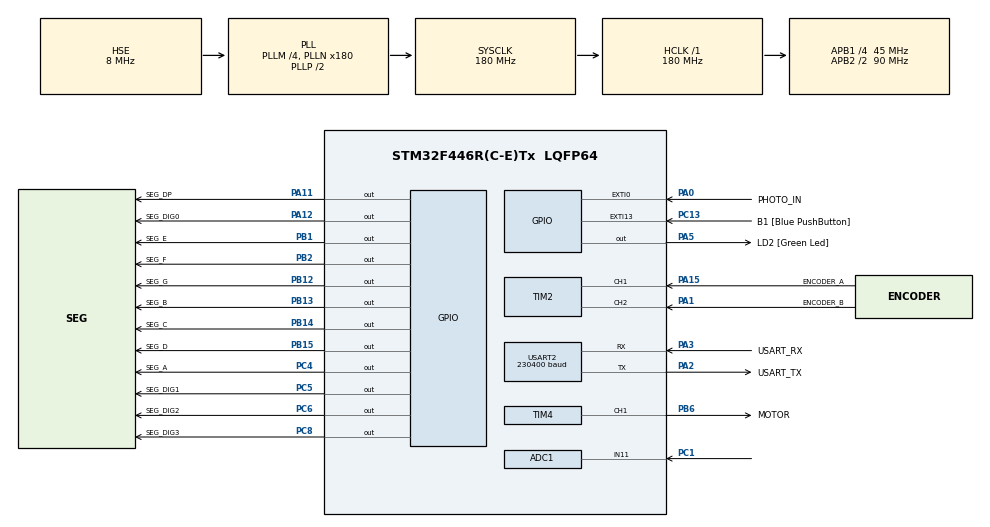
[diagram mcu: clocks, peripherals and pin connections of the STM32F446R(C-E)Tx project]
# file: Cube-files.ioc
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ADC1.Channel-1\#ChannelRegularConversion=ADC_CHANNEL_11
ADC1.ContinuousConvMode=ENABLE
ADC1.DMAContinuousRequests=ENABLE
ADC1.NbrOfConversion=1
ADC1.NbrOfConversionFlag=1
ADC1.Rank-1\#ChannelRegularConversion=1
ADC1.SamplingTime-1\#ChannelRegularConversion=ADC_SAMPLETIME_480CYCLES
ADC1.ScanConvMode=ENABLE
ADC1.master=1
Dma.ADC1.1.Direction=DMA_PERIPH_TO_MEMORY
Dma.ADC1.1.FIFOMode=DMA_FIFOMODE_DISABLE
Dma.ADC1.1.Instance=DMA2_Stream0
Dma.ADC1.1.MemDataAlignment=DMA_MDATAALIGN_WORD
Dma.ADC1.1.MemInc=DMA_MINC_ENABLE
Dma.ADC1.1.Mode=DMA_CIRCULAR
Dma.ADC1.1.PeriphDataAlignment=DMA_PDATAALIGN_WORD
Dma.ADC1.1.PeriphInc=DMA_PINC_DISABLE
Dma.ADC1.1.Priority=DMA_PRIORITY_LOW
Dma.Request0=USART2_TX
Dma.Request1=ADC1
Dma.USART2_TX.0.Direction=DMA_MEMORY_TO_PERIPH
Dma.USART2_TX.0.FIFOMode=DMA_FIFOMODE_DISABLE
Dma.USART2_TX.0.Instance=DMA1_Stream6
Dma.USART2_TX.0.MemDataAlignment=DMA_MDATAALIGN_BYTE
Dma.USART2_TX.0.MemInc=DMA_MINC_ENABLE
Dma.USART2_TX.0.Mode=DMA_NORMAL
Dma.USART2_TX.0.PeriphDataAlignment=DMA_PDATAALIGN_BYTE
Dma.USART2_TX.0.PeriphInc=DMA_PINC_DISABLE
Dma.USART2_TX.0.Priority=DMA_PRIORITY_LOW
FREERTOS.INCLUDE_vTaskDelayUntil=1
FREERTOS.Tasks01=mainTaskName,0,128,mainTask,As weak,NULL,Dynamic,NULL,NULL;printTaskName,-2,128,printTask,As external,NULL,Dynamic,NULL,NULL;motorTaskName,0,512,motorTask,As external,NULL,Dynamic,NULL,NULL;rpmDispTaskNam,-3,256,rpmDisplayTask,As external,NULL,Dynamic,NULL,NULL
FREERTOS.configENABLE_FPU=1
FREERTOS.configUSE_POSIX_ERRNO=0
Mcu.Family=STM32F4
Mcu.Name=STM32F446R(C-E)Tx
Mcu.Package=LQFP64
NVIC.ADC_IRQn=true\:5\:0\:false\:false\:true\:true\:true\:true\:true
NVIC.DMA1_Stream6_IRQn=true\:5\:0\:false\:false\:true\:true\:false\:true\:true
NVIC.DMA2_Stream0_IRQn=true\:5\:0\:false\:false\:true\:true\:false\:true\:true
NVIC.EXTI0_IRQn=true\:5\:0\:false\:false\:true\:true\:true\:true\:true
NVIC.PriorityGroup=NVIC_PRIORITYGROUP_4
NVIC.TIM8_TRG_COM_TIM14_IRQn=true\:15\:0\:false\:false\:true\:false\:false\:true\:true
NVIC.TimeBase=TIM8_TRG_COM_TIM14_IRQn
NVIC.TimeBaseIP=TIM14
NVIC.USART2_IRQn=true\:5\:0\:false\:false\:true\:true\:true\:true\:true
PA0-WKUP.GPIO_Label=PHOTO_IN
PA0-WKUP.GPIO_ModeDefaultEXTI=GPIO_MODE_IT_RISING
PA0-WKUP.GPIO_PuPd=GPIO_PULLDOWN
PA0-WKUP.Signal=GPXTI0
PA1.GPIO_Label=ENCODER_B
PA1.Signal=S_TIM2_CH2
PA11.GPIO_Label=SEG_DP
PA11.GPIO_PuPd=GPIO_PULLDOWN
PA11.Signal=GPIO_Output
PA12.GPIO_Label=SEG_DIG0
PA12.GPIO_PuPd=GPIO_NOPULL
PA12.Signal=GPIO_Output
PA13.GPIO_Label=TMS
PA13.Mode=Serial_Wire
PA13.Signal=SYS_JTMS-SWDIO
PA14.GPIO_Label=TCK
PA14.Mode=Serial_Wire
PA14.Signal=SYS_JTCK-SWCLK
PA15.GPIO_Label=ENCODER_A
PA15.Signal=S_TIM2_CH1_ETR
PA2.GPIO_Label=USART_TX
PA2.Mode=Asynchronous
PA2.Signal=USART2_TX
PA3.GPIO_Label=USART_RX
PA3.Mode=Asynchronous
PA3.Signal=USART2_RX
PA5.GPIO_Label=LD2 [Green Led]
PA5.Signal=GPIO_Output
PB1.GPIO_Label=SEG_E
PB1.GPIO_PuPd=GPIO_NOPULL
PB1.Signal=GPIO_Output
PB12.GPIO_Label=SEG_G
PB12.GPIO_PuPd=GPIO_NOPULL
PB12.Signal=GPIO_Output
PB13.GPIO_Label=SEG_B
PB13.GPIO_PuPd=GPIO_NOPULL
PB13.Signal=GPIO_Output
PB14.GPIO_Label=SEG_C
PB14.GPIO_PuPd=GPIO_NOPULL
PB14.Signal=GPIO_Output
PB15.GPIO_Label=SEG_D
PB15.GPIO_PuPd=GPIO_NOPULL
PB15.Signal=GPIO_Output
PB2.GPIO_Label=SEG_F
PB2.GPIO_PuPd=GPIO_NOPULL
PB2.Signal=GPIO_Output
PB3.GPIO_Label=SWO
PB3.Signal=SYS_JTDO-SWO
PB6.GPIO_Label=MOTOR
PB6.Signal=S_TIM4_CH1
PC1.Signal=ADCx_IN11
PC13.GPIO_Label=B1 [Blue PushButton]
PC13.GPIO_ModeDefaultEXTI=GPIO_MODE_IT_FALLING
PC13.Signal=GPXTI13
PC14-OSC32_IN.Mode=LSE-External-Oscillator
PC14-OSC32_IN.Signal=RCC_OSC32_IN
PC15-OSC32_OUT.Mode=LSE-External-Oscillator
PC15-OSC32_OUT.Signal=RCC_OSC32_OUT
PC4.GPIO_Label=SEG_A
PC4.GPIO_PuPd=GPIO_NOPULL
PC4.Signal=GPIO_Output
PC5.GPIO_Label=SEG_DIG1
PC5.GPIO_PuPd=GPIO_NOPULL
PC5.Signal=GPIO_Output
PC6.GPIO_Label=SEG_DIG2
PC6.GPIO_PuPd=GPIO_NOPULL
PC6.Signal=GPIO_Output
PC8.GPIO_Label=SEG_DIG3
PC8.GPIO_PuPd=GPIO_NOPULL
PC8.Signal=GPIO_Output
PH0-OSC_IN.Mode=HSE-External-Oscillator
PH0-OSC_IN.Signal=RCC_OSC_IN
PH1-OSC_OUT.Mode=HSE-External-Oscillator
PH1-OSC_OUT.Signal=RCC_OSC_OUT
ProjectManager.HeapSize=0x200
ProjectManager.StackSize=0x400
ProjectManager.TargetToolchain=Makefile
RCC.48MHZClocksFreq_Value=84000000
RCC.AHBFreq_Value=180000000
RCC.APB1CLKDivider=RCC_HCLK_DIV4
RCC.APB1Freq_Value=45000000
RCC.APB1TimFreq_Value=90000000
RCC.APB2CLKDivider=RCC_HCLK_DIV2
RCC.APB2Freq_Value=90000000
RCC.APB2TimFreq_Value=180000000
RCC.CortexFreq_Value=180000000
RCC.FLatency-AdvancedSettings=FLASH_LATENCY_5
RCC.HCLKFreq_Value=180000000
RCC.HSE_VALUE=8000000
RCC.HSI_VALUE=16000000
RCC.PLLM=4
RCC.PLLN=180
RCC.PLLSourceVirtual=RCC_PLLSOURCE_HSE
RCC.SYSCLKFreq_VALUE=180000000
RCC.SYSCLKSource=RCC_SYSCLKSOURCE_PLLCLK
RCC.USBFreq_Value=180000000
RCC.VCOOutputFreq_Value=360000000
SH.ADCx_IN11.0=ADC1_IN11,IN11
SH.S_TIM2_CH1_ETR.0=TIM2_CH1,Encoder_Interface
SH.S_TIM2_CH2.0=TIM2_CH2,Encoder_Interface
SH.S_TIM4_CH1.0=TIM4_CH1,PWM Generation1 CH1
TIM2.AutoReloadPreload=TIM_AUTORELOAD_PRELOAD_ENABLE
TIM2.EncoderMode=TIM_ENCODERMODE_TI12
TIM4.AutoReloadPreload=TIM_AUTORELOAD_PRELOAD_ENABLE
TIM4.Channel-PWM\ Generation1\ CH1=TIM_CHANNEL_1
TIM4.OCMode_PWM-PWM\ Generation1\ CH1=TIM_OCMODE_PWM1
TIM4.Period=19999
TIM4.Prescaler=89
TIM5.Prescaler=89
TIM5.TIM_MasterOutputTrigger=TIM_TRGO_RESET
USART2.BaudRate=230400
USART2.VirtualMode=VM_ASYNC
VP_FREERTOS_VS_CMSIS_V1.Mode=CMSIS_V1
VP_SYS_VS_tim14.Mode=TIM14
VP_TIM4_VS_ClockSourceINT.Mode=Internal
VP_TIM5_VS_ClockSourceINT.Mode=Internal
board=NUCLEO-F446RE

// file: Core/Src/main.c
/* USER CODE BEGIN Header */
/**
 ******************************************************************************
 * @file           : main.c
 * @brief          : Main program body
 ******************************************************************************
 * @attention
 *
 * Copyright (c) 2024 STMicroelectronics.
 * All rights reserved.
 *
 * This software is licensed under terms that can be found in the LICENSE file
 * in the root directory of this software component.
 * If no LICENSE file comes with this software, it is provided AS-IS.
 *
 ******************************************************************************
 */
/* USER CODE END Header */
#include "main.h"
#include "cmsis_os.h"
#include "adc.h"
#include "dma.h"
#include "tim.h"
#include "usart.h"
#include "gpio.h"

/* USER CODE BEGIN Includes */
#include "debug.h"
#include "bsp.h"
#include "userInit.h"
#include "encoder.h"
/* USER CODE END Includes */

void SystemClock_Config(void);
void MX_FREERTOS_Init(void);

int main(void)
{

  /* MCU Configuration--------------------------------------------------------*/

  /* Reset of all peripherals, Initializes the Flash interface and the Systick. */
  HAL_Init();

  /* Configure the system clock */
  SystemClock_Config();

  /* Initialize all configured peripherals */
  MX_GPIO_Init();
  MX_DMA_Init();
  MX_USART2_UART_Init();
  MX_TIM4_Init();
  MX_TIM2_Init();
  MX_ADC1_Init();
  MX_TIM5_Init();
  /* USER CODE BEGIN 2 */
  userInit();
  /* USER CODE END 2 */

  /* Call init function for freertos objects (in cmsis_os2.c) */
  MX_FREERTOS_Init();

  /* Start scheduler */
  osKernelStart();

  /* We should never get here as control is now taken by the scheduler */

  /* Infinite loop */
    while (1) {

    }
}

void SystemClock_Config(void)
{
  RCC_OscInitTypeDef RCC_OscInitStruct = {0};
  RCC_ClkInitTypeDef RCC_ClkInitStruct = {0};

  /** Configure the main internal regulator output voltage
  */
  __HAL_RCC_PWR_CLK_ENABLE();
  __HAL_PWR_VOLTAGESCALING_CONFIG(PWR_REGULATOR_VOLTAGE_SCALE1);

  /** Initializes the RCC Oscillators according to the specified parameters
  * in the RCC_OscInitTypeDef structure.
  */
  RCC_OscInitStruct.OscillatorType = RCC_OSCILLATORTYPE_HSE;
  RCC_OscInitStruct.HSEState = RCC_HSE_ON;
  RCC_OscInitStruct.PLL.PLLState = RCC_PLL_ON;
  RCC_OscInitStruct.PLL.PLLSource = RCC_PLLSOURCE_HSE;
  RCC_OscInitStruct.PLL.PLLM = 4;
  RCC_OscInitStruct.PLL.PLLN = 180;
  RCC_OscInitStruct.PLL.PLLP = RCC_PLLP_DIV2;
  RCC_OscInitStruct.PLL.PLLQ = 2;
  RCC_OscInitStruct.PLL.PLLR = 2;
  if (HAL_RCC_OscConfig(&RCC_OscInitStruct) != HAL_OK)
  {
    Error_Handler();
  }

  /** Activate the Over-Drive mode
  */
  if (HAL_PWREx_EnableOverDrive() != HAL_OK)
  {
    Error_Handler();
  }

  /** Initializes the CPU, AHB and APB buses clocks
  */
  RCC_ClkInitStruct.ClockType = RCC_CLOCKTYPE_HCLK|RCC_CLOCKTYPE_SYSCLK
                              |RCC_CLOCKTYPE_PCLK1|RCC_CLOCKTYPE_PCLK2;
  RCC_ClkInitStruct.SYSCLKSource = RCC_SYSCLKSOURCE_PLLCLK;
  RCC_ClkInitStruct.AHBCLKDivider = RCC_SYSCLK_DIV1;
  RCC_ClkInitStruct.APB1CLKDivider = RCC_HCLK_DIV4;
  RCC_ClkInitStruct.APB2CLKDivider = RCC_HCLK_DIV2;

  if (HAL_RCC_ClockConfig(&RCC_ClkInitStruct, FLASH_LATENCY_5) != HAL_OK)
  {
    Error_Handler();
  }
}

/* USER CODE BEGIN 4 */
int32_t last = 0;
float rpm = 0;
/* USER CODE END 4 */

void HAL_TIM_PeriodElapsedCallback(TIM_HandleTypeDef *htim)
{
  /* USER CODE BEGIN Callback 0 */

  if (htim->Instance == RPM_TIMER_HANDLE.Instance) {
    int32_t curr = encoderCount();
    rpm = (float)(curr - last) * SAMPLES_PER_SEC * RPS_TO_RPM / TICKS_PER_REV;
    last = curr;
  }
  /* USER CODE END Callback 0 */
  if (htim->Instance == TIM14) {
    HAL_IncTick();
  }
}

void Error_Handler(void)
{
    __disable_irq();
    while (1) {
    }
}

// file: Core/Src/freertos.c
/* USER CODE BEGIN Header */
/**
  ******************************************************************************
  * File Name          : freertos.c
  * Description        : Code for freertos applications
  ******************************************************************************
  * @attention
  *
  * Copyright (c) 2024 STMicroelectronics.
  * All rights reserved.
  *
  * This software is licensed under terms that can be found in the LICENSE file
  * in the root directory of this software component.
  * If no LICENSE file comes with this software, it is provided AS-IS.
  *
  ******************************************************************************
  */
/* USER CODE END Header */

#include "FreeRTOS.h"
#include "task.h"
#include "main.h"
#include "cmsis_os.h"

osThreadId mainTaskNameHandle;
osThreadId printTaskNameHandle;
osThreadId motorTaskNameHandle;
osThreadId rpmDispTaskNamHandle;

void mainTask(void const * argument);
extern void printTask(void const * argument);
extern void motorTask(void const * argument);
extern void rpmDisplayTask(void const * argument);

void MX_FREERTOS_Init(void); /* (MISRA C 2004 rule 8.1) */

/* GetIdleTaskMemory prototype (linked to static allocation support) */
void vApplicationGetIdleTaskMemory( StaticTask_t **ppxIdleTaskTCBBuffer, StackType_t **ppxIdleTaskStackBuffer, uint32_t *pulIdleTaskStackSize );

/* USER CODE BEGIN GET_IDLE_TASK_MEMORY */
static StaticTask_t xIdleTaskTCBBuffer;
static StackType_t xIdleStack[configMINIMAL_STACK_SIZE];

void vApplicationGetIdleTaskMemory( StaticTask_t **ppxIdleTaskTCBBuffer, StackType_t **ppxIdleTaskStackBuffer, uint32_t *pulIdleTaskStackSize )
{
  *ppxIdleTaskTCBBuffer = &xIdleTaskTCBBuffer;
  *ppxIdleTaskStackBuffer = &xIdleStack[0];
  *pulIdleTaskStackSize = configMINIMAL_STACK_SIZE;
  /* place for user code */
}
/* USER CODE END GET_IDLE_TASK_MEMORY */

void MX_FREERTOS_Init(void) {

  /* Create the thread(s) */
  /* definition and creation of mainTaskName */
  osThreadDef(mainTaskName, mainTask, osPriorityNormal, 0, 128);
  mainTaskNameHandle = osThreadCreate(osThread(mainTaskName), NULL);

  /* definition and creation of printTaskName */
  osThreadDef(printTaskName, printTask, osPriorityLow, 0, 128);
  printTaskNameHandle = osThreadCreate(osThread(printTaskName), NULL);

  /* definition and creation of motorTaskName */
  osThreadDef(motorTaskName, motorTask, osPriorityNormal, 0, 512);
  motorTaskNameHandle = osThreadCreate(osThread(motorTaskName), NULL);

  /* definition and creation of rpmDispTaskNam */
  osThreadDef(rpmDispTaskNam, rpmDisplayTask, osPriorityIdle, 0, 256);
  rpmDispTaskNamHandle = osThreadCreate(osThread(rpmDispTaskNam), NULL);

}

__weak void mainTask(void const * argument)
{
  for(;;)
  {
    osDelay(1);
  }
}
